# PIC32MK0512GPL100 register map
Vendor: Microchip
Registers are 32-bit, read-write, no defined reset value unless marked. A register's access mark holds for its fields unless they carry their own. Addresses are absolute, and some are shared; only a register's first bit layout is shown; [hi:lo] are bit positions; {n}, {i} and the like mark numbered series; 'fields as' and 'values as' point back to an identical list.

## CONFIG — Configuration words, addresses in PhysicalSpace
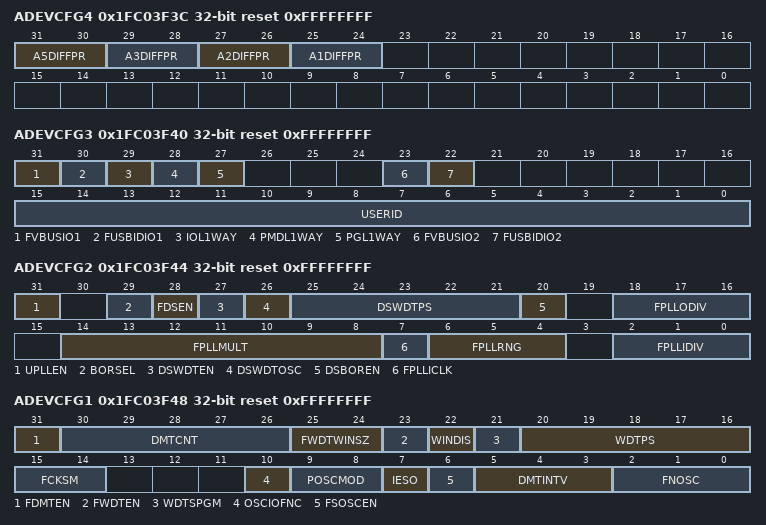
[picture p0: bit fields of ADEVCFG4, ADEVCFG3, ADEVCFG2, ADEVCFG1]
0x1FC03F3C ADEVCFG4 reset 0xFFFFFFFF
  [all] fields
    3=USE_PMOS_NMOS (Uses Both PMOS and NMOS Differential Pair); 2=USE_NMOS (Uses NMOS Differential Pair); 1=USE_PMOS (Use PMOS Differential Pair)
  [31:30] A5DIFFPR — Opamp 5 Differential Pair Selection
  [29:28] A3DIFFPR — Opamp 3 Differential Pair Selection
  [27:26] A2DIFFPR — Opamp 2 Differential Pair Selection
  [25:24] A1DIFFPR — Opamp 1 Differential Pair Selection
0x1FC03F40 ADEVCFG3 reset 0xFFFFFFFF
  [31] FVBUSIO1 — USB2 VBUSON Selection bit
    1=ON (VBUSON pin is controlled by the USB1 module); 0=OFF (VBUSON pin is controlled by the port function)
  [30] FUSBIDIO1 — USB1 USBID Selection
    1=ON (USBID pin is controlled by the USB1 module); 0=OFF (USBID pin is controlled by the port function)
  [29] IOL1WAY — Peripheral Pin Select Configuration
    1=ON (Allow only one reconfiguration); 0=OFF (Allow multiple reconfigurations)
  [28] PMDL1WAY — Peripheral Module Disable Configuration
    values as IOL1WAY
  [27] PGL1WAY — Permission Group Lock One Way Configuration bit
    values as IOL1WAY
  [23] FVBUSIO2 — USB2 VBUSON Selection bit
    1=ON (VBUSON pin is controlled by the USB2 module); 0=OFF (VBUSON pin is controlled by the port function)
  [22] FUSBIDIO2 — USB2 USBID Selection
    1=ON (USBID pin is controlled by the USB2 module); 0=OFF (USBID pin is controlled by the port function)
  [15:0] USERID
0x1FC03F44 ADEVCFG2 reset 0xFFFFFFFF
  [31] UPLLEN — USB PLL Enable
    1=OFF (USB PLL Disabled); 0=ON (USB PLL Enabled)
  [29] BORSEL — Brown-out trip voltage
    1=HIGH (BOR trip voltage 2.1v (Non-OPAMP deviced operation)); 0=LOW (BOR trip voltage 2.8v (OPAMP deviced operation))
  [28] FDSEN — Deep Sleep Enable
    0=OFF (Disable DSEN bit in DSCON); 1=ON (Enable DSEN bit in DSCON)
  [27] DSWDTEN — Deep Sleep Watchdog Timer Enable
    0=OFF (Disable DSWDT during Deep Sleep Mode); 1=ON (Enable DSWDT during Deep Sleep Mode)
  [26] DSWDTOSC — Deep Sleep WDT Reference Clock Selection
    0=SOSC (Select SOSC as DSWDT Reference Clock); 1=LPRC (Select LPRC as DSWDT Reference clock)
  [25:21] DSWDTPS — Deep Sleep Watchdog Timer Postscaler
    {v}=DSPS{v+1} (1:2^{v+5}) (v=0..31)
  [20] DSBOREN — Deep Sleep BOR Enable
    0=OFF (Disable ZPBOR during Deep Sleep Mode); 1=ON (Enable ZPBOR during Deep Sleep Mode)
  [18:16] FPLLODIV — System PLL Output Clock Divider
    1=DIV_2 (2x Divider); 2=DIV_4 (4x Divider); 3=DIV_8 (8x Divider); 4=DIV_16 (16x Divider); 7=DIV_32 (32x Divider)
  [14:8] FPLLMULT — System PLL Multiplier
    {v}=MUL_{v+1} (PLL Multiply by {v+1}) (v=0..127)
  [7] FPLLICLK — System PLL Input Clock Selection
    1=PLL_FRC (FRC is input to the System PLL); 0=PLL_POSC (POSC is input to the System PLL)
  [6:4] FPLLRNG — System PLL Input Range
    0=RANGE_BYPASS (Bypass); 1=RANGE_5_10_MHZ (5-10 MHz Input); 2=RANGE_8_16_MHZ (8-16 MHz Input); 3=RANGE_13_26_MHZ (13-26 MHz Input); 4=RANGE_21_42_MHZ (21-42 MHz Input); 5=RANGE_34_64_MHZ (34-64 MHz Input); 6=RANGE_54_64_MHZ (54-64 MHz Input)
  [2:0] FPLLIDIV — System PLL Input Divider
    {v}=DIV_{v+1} ({v+1}x Divider) (v=0..7)
0x1FC03F48 ADEVCFG1 reset 0xFFFFFFFF
  [31] FDMTEN — Deadman Timer Enable
    1=ON (Deadman Timer is enabled); 0=OFF (Deadman Timer is disabled)
  [30:26] DMTCNT — Deadman Timer Count Selection
    0=DMT8 (2^8 (256)); 1=DMT9 (2^9 (512)); 2=DMT10 (2^10 (1024)); 3=DMT11 (2^11 (2048)); 4=DMT12 (2^12 (4096)); 5=DMT13 (2^13 (8192)); 6=DMT14 (2^14 (16384)); 7=DMT15 (2^15 (32768)); 8=DMT16 (2^16 (65536)); 9=DMT17 (2^17 (131072)); 10=DMT18 (2^18 (262144)); 11=DMT19 (2^19 (524288)); 12=DMT20 (2^20 (1048576)); 13=DMT21 (2^21 (2097152)); 14=DMT22 (2^22 (4194304)); 15=DMT23 (2^23 (8388608)); 16=DMT24 (2^24 (16777216)); 17=DMT25 (2^25 (33554432)); 18=DMT26 (2^26 (67108864)); 19=DMT27 (2^27 (134217728)); 20=DMT28 (2^28 (268435456)); 21=DMT29 (2^29 (536870912)); 22=DMT30 (2^30 (1073741824)); 23=DMT31 (2^31 (2147483648))
  [25:24] FWDTWINSZ — Watchdog Timer Window Size
    3=WINSZ_25 (Window size is 25%); 2=WINSZ_37 (Window size is 37.5%); 1=WINSZ_50 (Window size is 50%); 0=WINSZ_75 (Window size is 75%)
  [23] FWDTEN — Watchdog Timer Enable
    1=ON (WDT Enabled); 0=OFF (WDT Disabled)
  [22] WINDIS — Watchdog Timer Window Mode
    1=NORMAL (Watchdog Timer is in non-Window mode); 0=WINDOW (Watchdog Timer is in Window mode)
  [21] WDTSPGM — Watchdog Timer Stop During Flash Programming
    0=RUN (WDT runs during Flash programming); 1=STOP (WDT stops during Flash programming)
  [20:16] WDTPS — Watchdog Timer Postscaler
    0=PS1 (1:1); 1=PS2 (1:2); 2=PS4 (1:4); 3=PS8 (1:8); 4=PS16 (1:16); 5=PS32 (1:32); 6=PS64 (1:64); 7=PS128 (1:128); 8=PS256 (1:256); 9=PS512 (1:512); 10=PS1024 (1:1024); 11=PS2048 (1:2048); 12=PS4096 (1:4096); 13=PS8192 (1:8192); 14=PS16384 (1:16384); 15=PS32768 (1:32768); 0b1x000=PS65536 (1:65536); 0b1x001=PS131072 (1:131072); 0b1x010=PS262144 (1:262144); 0b1x011=PS524288 (1:524288); 0b1x1xx=PS1048576 (1:1048576)
  [15:14] FCKSM — Clock Switching and Monitor Selection
    0=CSDCMD (Clock Switch Disabled, FSCM Disabled); 1=CSECMD (Clock Switch Enabled, FSCM Disabled); 2=CSDCME (Clock Switch Disabled, FSCM Enabled); 3=CSECME (Clock Switch Enabled, FSCM Enabled)
  [10] OSCIOFNC — CLKO Output Signal Active on the OSCO Pin
    0=ON (Enabled); 1=OFF (Disabled)
  [9:8] POSCMOD — Primary Oscillator Configuration
    0=EC (External clock mode); 2=HS (HS osc mode); 3=OFF (Primary osc disabled)
  [7] IESO — Internal/External Switch Over
    1=ON (Enabled); 0=OFF (Disabled)
  [6] FSOSCEN — Secondary Oscillator Enable
    1=ON (Enable Secondary Oscillator); 0=OFF (Disable Secondary Oscillator)
  [5:3] DMTINTV — DMT Count Window Interval
    0=WIN_0 (Window/Interval value is zero); 1=WIN_1_2 (Window/Interval value is 1/2 counter value); 2=WIN_3_4 (Window/Interval value is 3/4 counter value); 3=WIN_7_8 (Window/Interval value is 7/8 counter value); 4=WIN_15_16 (Window/Interval value is 15/16 counter value); 5=WIN_31_32 (Window/Interval value is 31/32 counter value); 6=WIN_63_64 (Window/Interval value is 63/64 counter value); 7=WIN_127_128 (Window/Interval value is 127/128 counter value)
  [2:0] FNOSC — Oscillator Selection Bits
    0=FRC (Internal Fast RC (FRC)); 1=SPLL (System PLL); 2=POSC (Primary Osc (HS,EC)); 3=UPLL (USB PLL (UPLL)); 4=SOSC (Low Power Secondary Osc (SOSC)); 5=LPRC (Low Power RC Osc (LPRC))
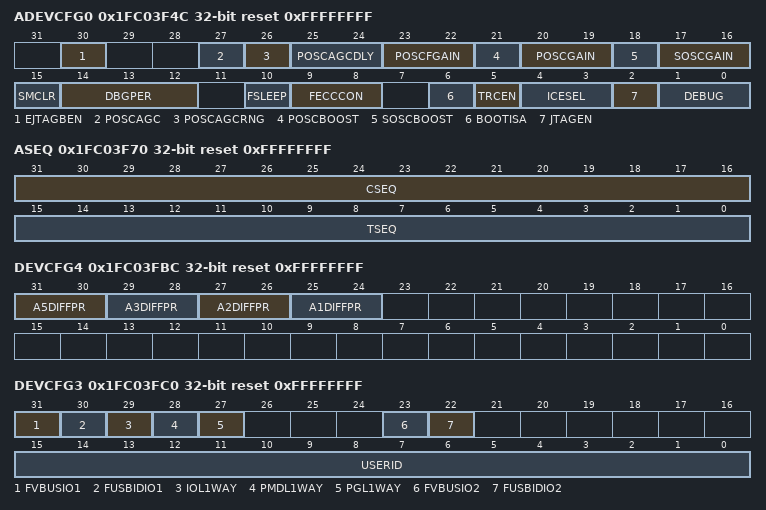
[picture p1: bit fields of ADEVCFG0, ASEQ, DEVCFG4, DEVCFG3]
0x1FC03F4C ADEVCFG0 reset 0xFFFFFFFF
  [30] EJTAGBEN — EJTAG Boot Enable
    0=REDUCED (Reduced EJTAG functionality); 1=NORMAL (Normal EJTAG functionality)
  [27] POSCAGC — Primary Oscillator Gain Control bit
    1=Automatic Gain Control for Oscillator; 0=Manual Gain Control of Oscillator
  [26] POSCAGCRNG — AGC Lock Range bit
    1=ONE_X (Range 1x); 0=FIVE_X (Range 5x)
  [25:24] POSCAGCDLY — AGC Gain Search Step Settling Time Control
    3=AGCRNG_x_25ms (Settling time = 25ms x AGCRNG); 2=AGCRNG_x_6_25ms (Settling time = 6.25ms x AGCRNG); 1=AGCRNG_x_400ms (Settling time = 400ms x AGCRNG); 0=AGCRNG_x_100ms (Settling time = 100ms x AGCRNG)
  [23:22] POSCFGAIN — Primary Oscillator Fine Gain Control bits
    {v}=G{v} (Gain is G{v}) (v=0..3)
  [21] POSCBOOST — Primary Oscillator Boost Kick Start Enable bit
    1=ON (Boost the kick start of the oscillator); 0=OFF (Normal start of the oscillator)
  [20:19] POSCGAIN — Primary Oscillator Coarse Gain Control bits
    3=G3 (Gain Level 3 (highest)); 2=G2 (Gain Level 2); 1=G1 (Gain Level 1); 0=G0 (Gain Level 0 (Lowest))
  [18] SOSCBOOST — Secondary Oscillator Boost Kick Start Enable bit
    values as POSCBOOST
  [17:16] SOSCGAIN — Secondary Oscillator Gain Control bits
    {v}=G{v} (Gain is G{v}) (v=0..3)
  [15] SMCLR — Soft Master Clear Enable
    0=MCLR_POR (MCLR pin generates an emulated POR Reset); 1=MCLR_NORM (MCLR pin generates a normal system Reset)
  [14:12] DBGPER — Debug Mode CPU Access Permission
    4=ALLOW_PG2 (Allow CPU access to Permission Group 2 permission regions); 2=ALLOW_PG1 (Allow CPU access to Permission Group 1 permission regions); 1=ALLOW_PG0 (Allow CPU access to Permission Group 0 permission regions); 3=PG_1_0 (PG0: Allow PG1: Allow PG2: Deny); 5=PG_2_0 (PG0: Allow PG1: Deny PG2: Allow); 6=PG_2_1 (PG0: Deny PG1: Allow PG2: Allow); 7=PG_ALL (Allow CPU access to all permission regions); 0=PG_NONE (Deny CPU access to all permission regions)
  [10] FSLEEP — Flash Sleep Mode
    0=VREGS (Flash power down is controlled by the VREGS bit); 1=OFF (Flash is powered down when the device is in Sleep mode)
  [9:8] FECCCON — Dynamic Flash ECC Configuration Bits
    3=ECC_DECC_DISABLE_ECCON_WRITABLE (ECC and Dynamic ECC are disabled (ECCCON<1:0> bits are writable)); 2=ECC_DECC_DISABLE_ECCON_LOCKED (ECC and Dynamic ECC are disabled (ECCCON<1:0> bits are locked)); 1=DECC_ENABLE (Dynamic Flash ECC is enabled (ECCCON<1:0> bits are locked)); 0=ECC_ENABLE (Flash ECC is enabled (ECCCON<1:0> bits are locked; disables word Flash writes))
  [6] BOOTISA — Boot ISA Selection
    1=MIPS32 (Boot code and Exception code is MIPS32); 0=MICROMIPS (Boot code and Exception code is microMIPS)
  [5] TRCEN — Trace Enable
    1=ON (Trace features in the CPU are enabled); 0=OFF (Trace features in the CPU are disabled)
  [4:3] ICESEL — ICE/ICD Comm Channel Select
    3=ICS_PGx1 (Communicate on PGEC1/PGED1); 2=ICS_PGx2 (Communicate on PGEC2/PGED2); 1=ICS_PGx3 (Communicate on PGEC3/PGED3)
  [2] JTAGEN — JTAG Enable
    1=ON (JTAG Port Enabled); 0=OFF (JTAG Disabled)
  [1:0] DEBUG — Background Debugger Enable
    0=ON (Debugger is enabled); 3=OFF (Debugger is disabled)
0x1FC03F5C ADEVCP reset 0xFFFFFFFF
  [28] CP — Code Protect
    0=ON (Protection Enabled); 1=OFF (Protection Disabled)
0x1FC03F6C ADEVSIGN access not given reset 0x7FFFFFFF
0x1FC03F70 ASEQ reset 0xFFFFFFFF
  [31:16] CSEQ — Boot Flash Complement Sequence Number
  [15:0] TSEQ — Boot Flash True Sequence Number
0x1FC03FBC DEVCFG4 reset 0xFFFFFFFF
  fields as ADEVCFG4
0x1FC03FC0 DEVCFG3 reset 0xFFFFFFFF
  fields as ADEVCFG3
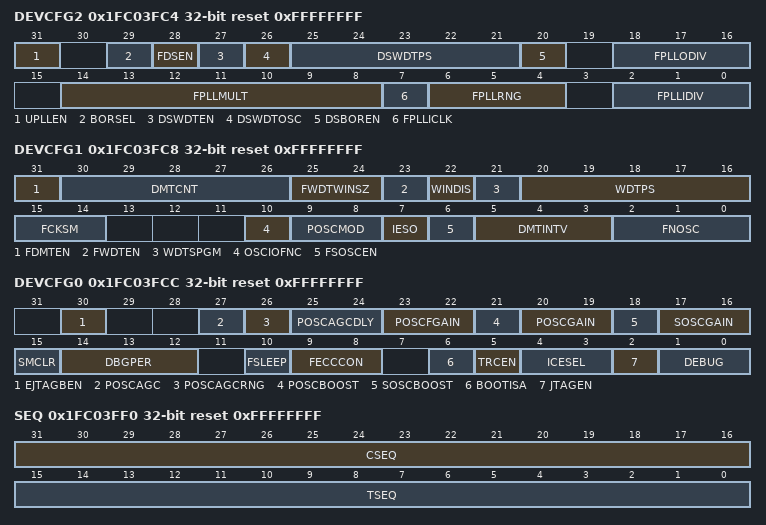
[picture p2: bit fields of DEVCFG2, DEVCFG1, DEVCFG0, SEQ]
0x1FC03FC4 DEVCFG2 reset 0xFFFFFFFF
  fields as ADEVCFG2
0x1FC03FC8 DEVCFG1 reset 0xFFFFFFFF
  fields as ADEVCFG1
0x1FC03FCC DEVCFG0 reset 0xFFFFFFFF
  fields as ADEVCFG0
0x1FC03FDC DEVCP reset 0xFFFFFFFF
  fields as ADEVCP
0x1FC03FEC DEVSIGN access not given reset 0x7FFFFFFF
0x1FC03FF0 SEQ reset 0xFFFFFFFF
  fields as ASEQ
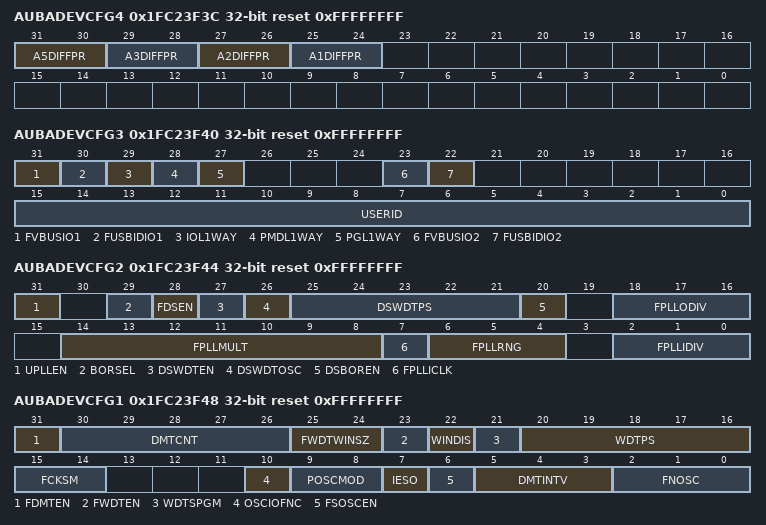
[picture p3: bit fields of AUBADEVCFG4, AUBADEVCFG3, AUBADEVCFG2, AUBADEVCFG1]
0x1FC23F3C AUBADEVCFG4 reset 0xFFFFFFFF
  fields as ADEVCFG4
0x1FC23F40 AUBADEVCFG3 reset 0xFFFFFFFF
  fields as ADEVCFG3
0x1FC23F44 AUBADEVCFG2 reset 0xFFFFFFFF
  fields as ADEVCFG2
0x1FC23F48 AUBADEVCFG1 reset 0xFFFFFFFF
  fields as ADEVCFG1
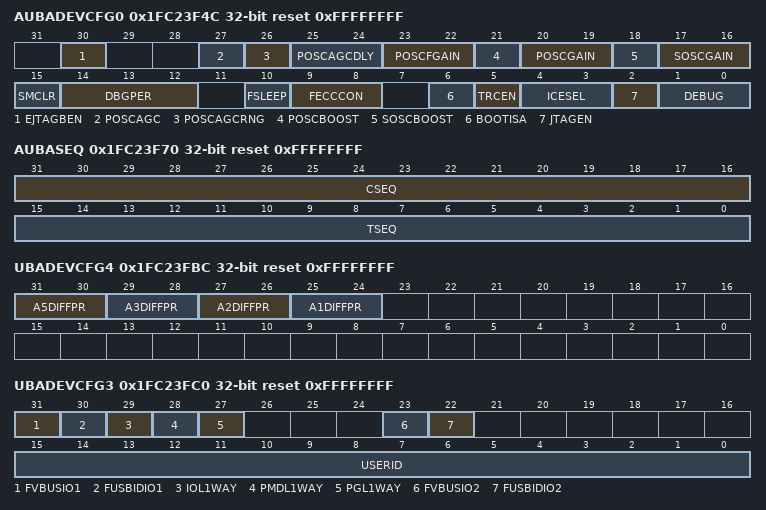
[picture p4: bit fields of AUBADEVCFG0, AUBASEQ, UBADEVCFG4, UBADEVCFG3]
0x1FC23F4C AUBADEVCFG0 reset 0xFFFFFFFF
  fields as ADEVCFG0
0x1FC23F5C AUBADEVCP reset 0xFFFFFFFF
  fields as ADEVCP
0x1FC23F6C AUBADEVSIGN access not given reset 0x7FFFFFFF
0x1FC23F70 AUBASEQ reset 0xFFFFFFFF
  fields as ASEQ
0x1FC23FBC UBADEVCFG4 reset 0xFFFFFFFF
  fields as ADEVCFG4
0x1FC23FC0 UBADEVCFG3 reset 0xFFFFFFFF
  fields as ADEVCFG3
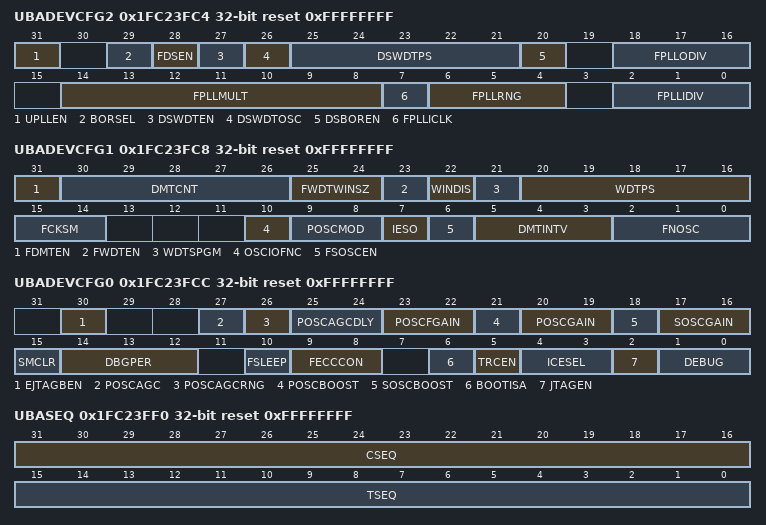
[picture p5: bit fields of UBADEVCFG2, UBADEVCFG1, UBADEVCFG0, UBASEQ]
0x1FC23FC4 UBADEVCFG2 reset 0xFFFFFFFF
  fields as ADEVCFG2
0x1FC23FC8 UBADEVCFG1 reset 0xFFFFFFFF
  fields as ADEVCFG1
0x1FC23FCC UBADEVCFG0 reset 0xFFFFFFFF
  fields as ADEVCFG0
0x1FC23FDC UBADEVCP reset 0xFFFFFFFF
  fields as ADEVCP
0x1FC23FEC UBADEVSIGN access not given reset 0x7FFFFFFF
0x1FC23FF0 UBASEQ reset 0xFFFFFFFF
  fields as ASEQ
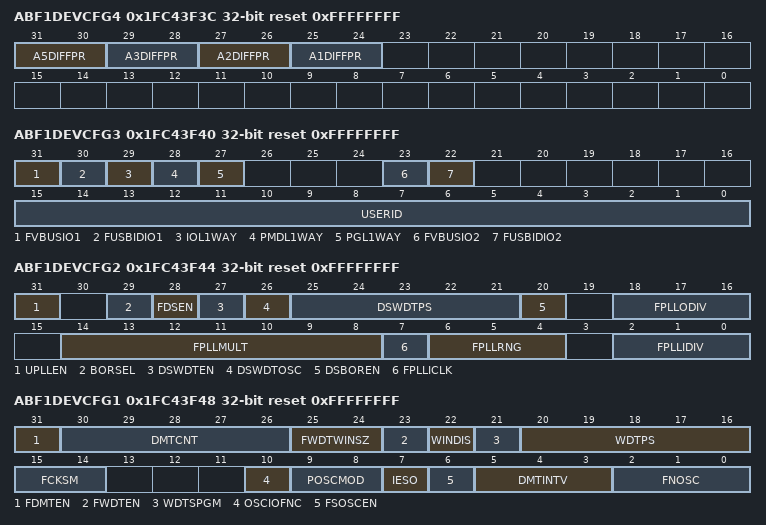
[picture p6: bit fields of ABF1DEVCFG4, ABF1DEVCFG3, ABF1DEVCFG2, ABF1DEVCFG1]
0x1FC43F3C ABF1DEVCFG4 reset 0xFFFFFFFF
  fields as ADEVCFG4
0x1FC43F40 ABF1DEVCFG3 reset 0xFFFFFFFF
  fields as ADEVCFG3
0x1FC43F44 ABF1DEVCFG2 reset 0xFFFFFFFF
  fields as ADEVCFG2
0x1FC43F48 ABF1DEVCFG1 reset 0xFFFFFFFF
  fields as ADEVCFG1
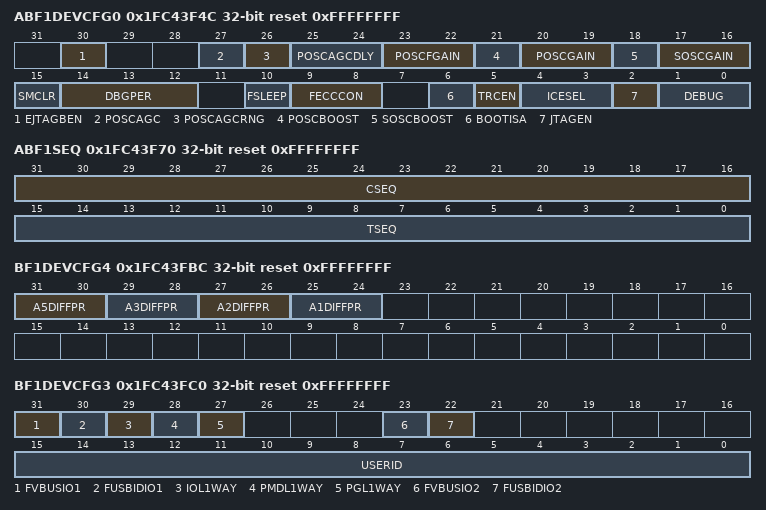
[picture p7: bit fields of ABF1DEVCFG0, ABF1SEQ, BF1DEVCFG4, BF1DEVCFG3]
0x1FC43F4C ABF1DEVCFG0 reset 0xFFFFFFFF
  fields as ADEVCFG0
0x1FC43F5C ABF1DEVCP reset 0xFFFFFFFF
  fields as ADEVCP
0x1FC43F6C ABF1DEVSIGN access not given reset 0x7FFFFFFF
0x1FC43F70 ABF1SEQ reset 0xFFFFFFFF
  fields as ASEQ
0x1FC43FBC BF1DEVCFG4 reset 0xFFFFFFFF
  fields as ADEVCFG4
0x1FC43FC0 BF1DEVCFG3 reset 0xFFFFFFFF
  fields as ADEVCFG3
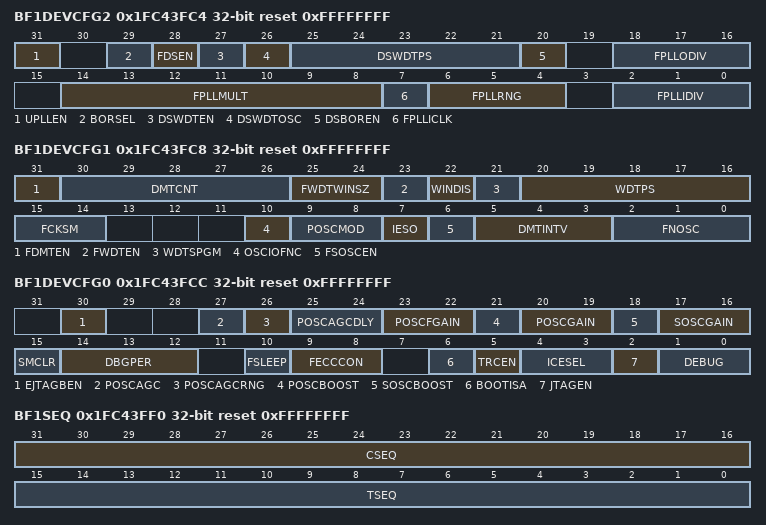
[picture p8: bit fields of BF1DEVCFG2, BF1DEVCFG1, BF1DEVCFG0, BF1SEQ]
0x1FC43FC4 BF1DEVCFG2 reset 0xFFFFFFFF
  fields as ADEVCFG2
0x1FC43FC8 BF1DEVCFG1 reset 0xFFFFFFFF
  fields as ADEVCFG1
0x1FC43FCC BF1DEVCFG0 reset 0xFFFFFFFF
  fields as ADEVCFG0
0x1FC43FDC BF1DEVCP reset 0xFFFFFFFF
  fields as ADEVCP
0x1FC43FEC BF1DEVSIGN access not given reset 0x7FFFFFFF
0x1FC43FF0 BF1SEQ reset 0xFFFFFFFF
  fields as ASEQ
{0x1FC45000+4i} DEVADC{i} reset 0xFFFFFFFF (i=0..5)
  [31:0] ADCCALDATA — ADC Calibration Data
0x1FC45018 DEVADC7 reset 0xFFFFFFFF
  [31:0] ADCCALDATA — ADC Calibration Data
{0x1FC45020+4i} DEVSN{i} ro reset 0xFFFFFFFF (i=0..3)
  [31:0] SN
0x1FC45030 DEVEE0 reset 0xFFFFFFFF — EE Data Calibration Data
  [31:0] EECALDATA
{0x1FC45030+4i} DEVEE{i} reset 0xFFFFFFFF (i=1..3)
  [31:0] EECALDATA — EE Data Calibration Data
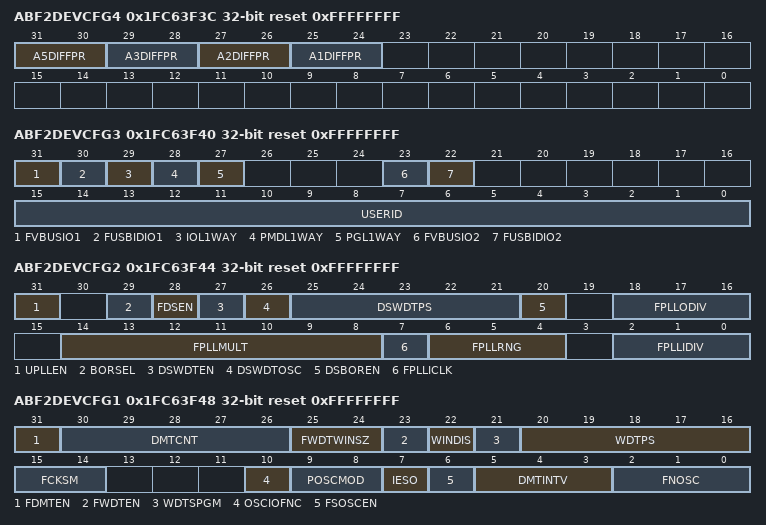
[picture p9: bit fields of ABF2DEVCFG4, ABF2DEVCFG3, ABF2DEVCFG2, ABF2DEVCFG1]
0x1FC63F3C ABF2DEVCFG4 reset 0xFFFFFFFF
  fields as ADEVCFG4
0x1FC63F40 ABF2DEVCFG3 reset 0xFFFFFFFF
  fields as ADEVCFG3
0x1FC63F44 ABF2DEVCFG2 reset 0xFFFFFFFF
  fields as ADEVCFG2
0x1FC63F48 ABF2DEVCFG1 reset 0xFFFFFFFF
  fields as ADEVCFG1
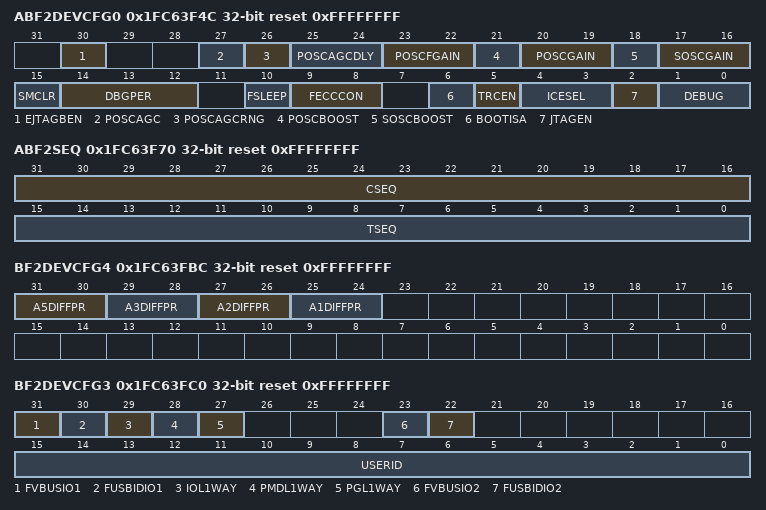
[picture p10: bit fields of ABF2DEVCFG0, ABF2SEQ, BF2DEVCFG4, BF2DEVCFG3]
0x1FC63F4C ABF2DEVCFG0 reset 0xFFFFFFFF
  fields as ADEVCFG0
0x1FC63F5C ABF2DEVCP reset 0xFFFFFFFF
  fields as ADEVCP
0x1FC63F6C ABF2DEVSIGN access not given reset 0x7FFFFFFF
0x1FC63F70 ABF2SEQ reset 0xFFFFFFFF
  fields as ASEQ
0x1FC63FBC BF2DEVCFG4 reset 0xFFFFFFFF
  fields as ADEVCFG4
0x1FC63FC0 BF2DEVCFG3 reset 0xFFFFFFFF
  fields as ADEVCFG3
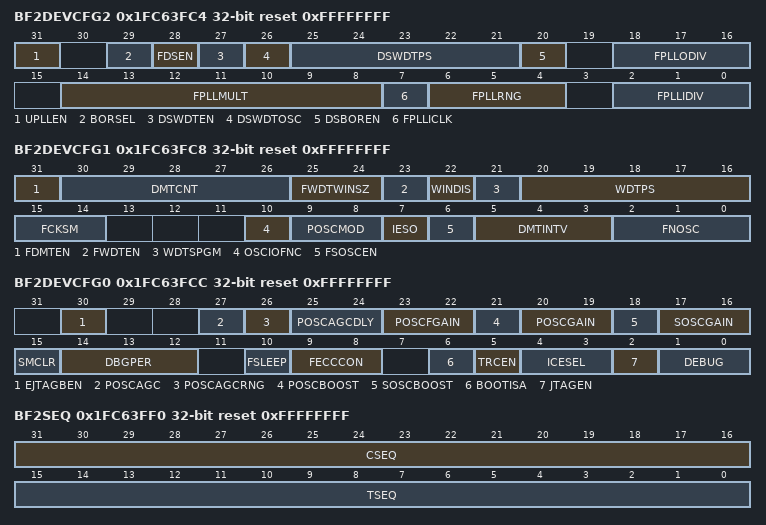
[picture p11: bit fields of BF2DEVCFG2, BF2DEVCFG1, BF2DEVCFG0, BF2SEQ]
0x1FC63FC4 BF2DEVCFG2 reset 0xFFFFFFFF
  fields as ADEVCFG2
0x1FC63FC8 BF2DEVCFG1 reset 0xFFFFFFFF
  fields as ADEVCFG1
0x1FC63FCC BF2DEVCFG0 reset 0xFFFFFFFF
  fields as ADEVCFG0
0x1FC63FDC BF2DEVCP reset 0xFFFFFFFF
  fields as ADEVCP
0x1FC63FEC BF2DEVSIGN access not given reset 0x7FFFFFFF
0x1FC63FF0 BF2SEQ reset 0xFFFFFFFF
  fields as ASEQ
